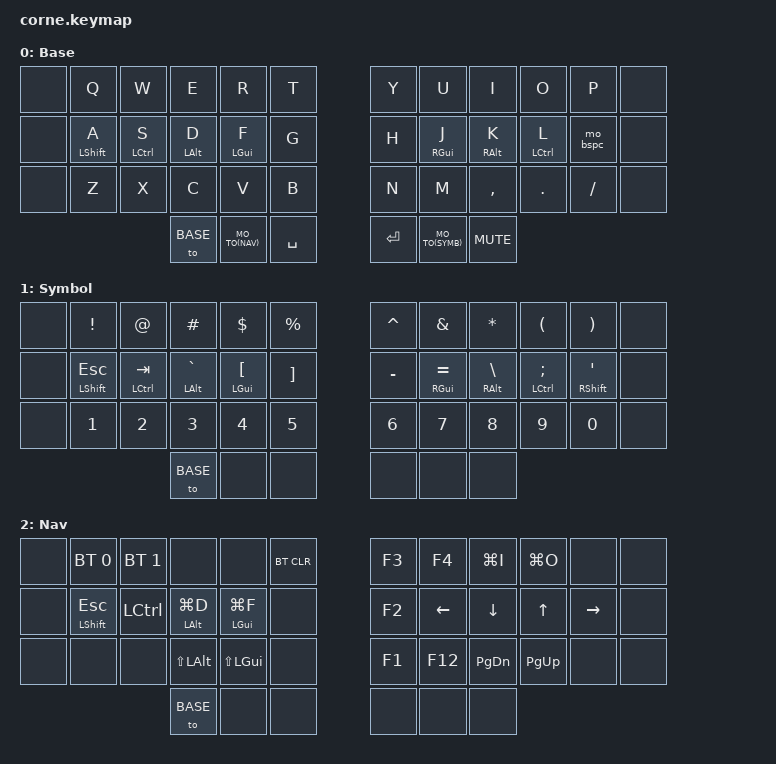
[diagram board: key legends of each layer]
/*
 * Copyright (c) 2020 The ZMK Contributors
 *
 * SPDX-License-Identifier: MIT
 */

#include <behaviors.dtsi>
#include <dt-bindings/zmk/keys.h>
#include <dt-bindings/zmk/bt.h>

#define BASE    0
#define SYMB    1
#define NAV     2
#define MO_TO(layer) &mo_to layer layer
#define MO_KEY_TO(key, layer) &mo_key_to key layer

&mt {
    flavor = "tap-preferred";
};

/ {
    behaviors {
        mo_to: behavior_mo_to {
            compatible = "zmk,behavior-hold-tap";
            #binding-cells = <2>;
            flavor = "hold-preferred";
            tapping-term-ms = <250>;
            bindings = <&mo>, <&to>;
        };

        mo_key_to: behavior_mo_key_to {
            compatible = "zmk,behavior-hold-tap";
            #binding-cells = <2>;
            flavor = "hold-preferred";
            tapping-term-ms = <250>;
            bindings = <&kp>, <&to>;
        };

        mo_base: behavior_mo_base {
            compatible = "zmk,behavior-mod-morph";
            #binding-cells = <0>;
            bindings = <MO_TO(SYMB)>, <MO_TO(NAV)>;
            mods = <(MOD_RGUI)>;
        };

        mo_bspc: behavior_mo_bspc {
            compatible = "zmk,behavior-mod-morph";
            #binding-cells = <0>;
            bindings = <&mt RSHIFT BSPC>, <&kp BSPC>;
            mods = <(MOD_LCTL)>;
        };
    };

    keymap {
        compatible = "zmk,keymap";

        base_layer {
            display-name = "Base";                              
            bindings = <
                // ╭──────────┬──────────┬──────────┬──────────┬──────────┬──────────╮   ╭──────────┬──────────┬──────────┬──────────┬──────────┬──────────╮
                // │          │          │          │          │          │          │   │          │          │          │          │          │          │
                // │          │ Q        │ W        │ E        │ R        │ T        │   │ Y        │ U        │ I        │ O        │ P        │          │
                     &none      &kp Q      &kp W      &kp E      &kp R      &kp T          &kp Y     &kp U       &kp I      &kp O      &kp P      &none
                // ├──────────┼──────────┼──────────┼──────────┼──────────┤──────────┤   ├──────────┼──────────┼──────────┼──────────┼──────────┼──────────┤
                // │          │   _SHIFT │    _CTRL │     _OPT │     _CMD │          │   │          │     _CMD │     _OPT │    _CTRL │   _SHIFT │          │
                // │          │ A        │ S        │ D        │ F        │ G        │   │ H        │ J        │ K        │ L        │ BSPC     │          │
                     &none    &mt LSHFT A  &mt LCTRL S &mt LALT D &mt LGUI F &kp G         &kp H    &mt RGUI J &mt RALT K   &mt LCTRL L &mo_bspc  &none
                // ├──────────┼──────────┼──────────┼──────────┼──────────┤──────────┤   ├──────────┼──────────┼──────────┼──────────┼──────────┼──────────┤
                // │          │          │          │          │          │          │   │          │          │ LT       │ GT       │ ?        │          │
                // │          │ Z        │ X        │ C        │ V        │ B        │   │ N        │ M        │ ,        │ .        │ /        │          │
                     &none      &kp Z      &kp X      &kp C      &kp V      &kp B          &kp N      &kp M      &kp COMMA  &kp DOT    &kp FSLH   &none
                // ╰──────────┴──────────┴──────────┼──────────┼──────────┤──────────┤   ├──────────┼──────────┼──────────┼──────────┴──────────┴──────────╯
                                                      &to BASE   MO_TO(NAV) &kp SPACE      &kp RET  MO_TO(SYMB)  &kp C_MUTE
                //                                  ╰──────────┴──────────┴──────────╯   ╰──────────┴──────────┴──────────╯
            >;
        };

        symbol_layer {
            display-name = "Symbol";
            bindings = <
                // ╭──────────┬──────────┬──────────┬──────────┬──────────┬──────────╮   ╭──────────┬──────────┬──────────┬──────────┬──────────┬──────────╮
                // │          │          │          │          │          │          │   │          │          │          │          │          │          │
                // │          │ !        │ @      € │ #        │ $        │ %        │   │ ^        │ &        │ *        │ (        │ )        │          │
                     &none      &kp EXCL   &kp AT     &kp HASH   &kp DLLR   &kp PRCNT      &kp CARET  &kp AMPS   &kp ASTRK  &kp LPAR   &kp RPAR   &none
                // ├──────────┼──────────┼──────────┼──────────┼──────────┤──────────┤   ├──────────┼──────────┼──────────┼──────────┼──────────┼──────────┤
                // │          │   _SHIFT │    _CTRL │ ~   _OPT │ {   _CMD │ }        │   │ _        │ +   _CMD │ |   _OPT │ :  _CTRL │ " _SHIFT │          │
                // │          │ ESC      │ TAB      │ `        │ [        │ ]        │   │ -        │ =        │ \        │ ;      … │ '        │          │
                   &none &mt LSHFT ESC &mt LCTRL TAB &mt LALT GRAVE &mt LGUI LBKT &kp RBKT &kp MINUS &mt RGUI EQUAL &mt RALT BSLH &mt LCTRL SEMI &mt RSHFT APOS &none
                // ├──────────┼──────────┼──────────┼──────────┼──────────┤──────────┤   ├──────────┼──────────┼──────────┼──────────┼──────────┼──────────┤
                // │          │          │          │          │          │          │   │          │          │          │          │          │          │
                // │          │ 1        │ 2        │ 3        │ 4        │ 5        │   │ 6        │ 7        │ 8        │ 9        │ 0        │          │
                     &none      &kp N1     &kp N2     &kp N3     &kp N4     &kp N5         &kp N6     &kp N7     &kp N8     &kp N9     &kp N0     &none
                // ╰──────────┴──────────┴──────────┼──────────┼──────────┤──────────┤   ├──────────┼──────────┼──────────┼──────────┴──────────┴──────────╯
                                                      &to BASE   &none      &none          &none      &none      &none
                //                                  ╰──────────┴──────────┴──────────╯   ╰──────────┴──────────┴──────────╯
            >;
        };

        navigation_layer {
            display-name = "Nav";
            bindings = <
                // ╭──────────┬──────────┬──────────┬──────────┬──────────┬──────────╮   ╭──────────┬──────────┬──────────┬──────────┬──────────┬──────────╮
                // │          │          │          │          │          │          │   │          │          │          │          │          │          │
                // │          │ 0        │ 1        │          │          │ CLR      │   │ F3       │ F4       │ CMD(I)   │ CMD(O)   │          │          │
                     &none    &bt BT_SEL 0 &bt BT_SEL 1 &none    &none      &bt BT_CLR     &kp F3     &kp F4     &kp LG(I)  &kp LG(O)  &none      &none
                // ├──────────┼──────────┼──────────┼──────────┼──────────┤──────────┤   ├──────────┼──────────┼──────────┼──────────┼──────────┼──────────┤
                // │          │   _SHIFT │          │     _OPT │     _CMD │          │   │          │          │          │          │          │          │
                // │          │ ESC      │ LCTRL    │ CMD(D)   │ CMD(F)   │          │   │ F2       │ LEFT     │ DOWN     │ UP       │ RIGHT    │          │
                    &none &mt LSHFT ESC  &kp LCTRL  &mt LALT LG(D) &mt LGUI LG(F) &none    &kp F2     &kp LEFT   &kp DOWN   &kp UP     &kp RIGHT  &none
                // ├──────────┼──────────┼──────────┼──────────┼──────────┤──────────┤   ├──────────┼──────────┼──────────┼──────────┼──────────┼──────────┤
                // │          │          │          │          │          │          │   │          │          │          │          │          │          │
                // │          │          │          │          │          │          │   │ F1       │ F12      │ PG_DN    │ PG_UP    │          │          │
                    &none       &none      &none    &kp LS(LALT) &kp LS(LGUI) &none        &kp F1     &kp F12    &kp PG_DN  &kp PG_UP  &none      &none
                // ╰──────────┴──────────┴──────────┼──────────┼──────────┤──────────┤   ├──────────┼──────────┼──────────┼──────────┴──────────┴──────────╯
                                                      &to BASE   &none      &none          &none      &none      &none  
                //                                  ╰──────────┴──────────┴──────────╯   ╰──────────┴──────────┴──────────╯
            >;
        };
    };
};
